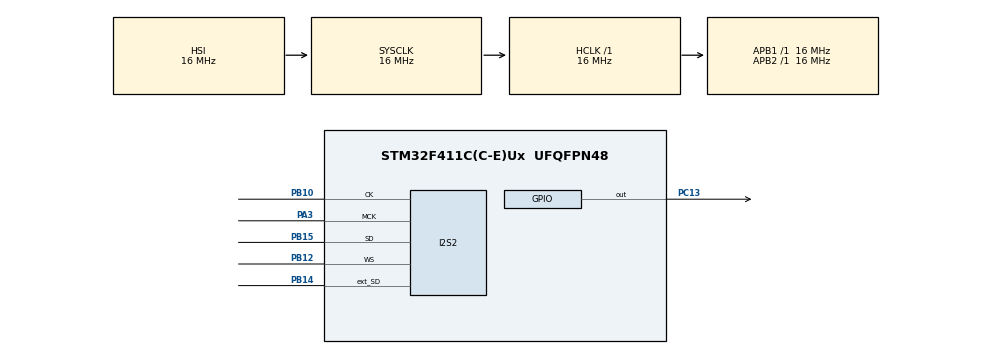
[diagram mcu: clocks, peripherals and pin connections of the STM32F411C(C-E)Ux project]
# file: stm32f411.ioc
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Dma.I2S2_EXT_RX.0.Direction=DMA_PERIPH_TO_MEMORY
Dma.I2S2_EXT_RX.0.FIFOMode=DMA_FIFOMODE_DISABLE
Dma.I2S2_EXT_RX.0.Instance=DMA1_Stream3
Dma.I2S2_EXT_RX.0.MemDataAlignment=DMA_MDATAALIGN_HALFWORD
Dma.I2S2_EXT_RX.0.MemInc=DMA_MINC_ENABLE
Dma.I2S2_EXT_RX.0.Mode=DMA_NORMAL
Dma.I2S2_EXT_RX.0.PeriphDataAlignment=DMA_PDATAALIGN_HALFWORD
Dma.I2S2_EXT_RX.0.PeriphInc=DMA_PINC_DISABLE
Dma.I2S2_EXT_RX.0.Priority=DMA_PRIORITY_LOW
Dma.Request0=I2S2_EXT_RX
Dma.Request1=SPI2_TX
Dma.SPI2_TX.1.Direction=DMA_MEMORY_TO_PERIPH
Dma.SPI2_TX.1.FIFOMode=DMA_FIFOMODE_DISABLE
Dma.SPI2_TX.1.Instance=DMA1_Stream4
Dma.SPI2_TX.1.MemDataAlignment=DMA_MDATAALIGN_HALFWORD
Dma.SPI2_TX.1.MemInc=DMA_MINC_ENABLE
Dma.SPI2_TX.1.Mode=DMA_CIRCULAR
Dma.SPI2_TX.1.PeriphDataAlignment=DMA_PDATAALIGN_HALFWORD
Dma.SPI2_TX.1.PeriphInc=DMA_PINC_DISABLE
Dma.SPI2_TX.1.Priority=DMA_PRIORITY_LOW
I2S2.AudioFreq=I2S_AUDIOFREQ_44K
I2S2.DataFormat=I2S_DATAFORMAT_24B
I2S2.ErrorAudioFreq=-5.3 %
I2S2.FullDuplexMode=I2S_FULLDUPLEXMODE_ENABLE
I2S2.Instance=SPI$Index
I2S2.RealAudioFreq=41.666 KHz
I2S2.VirtualMode=I2S_MODE_MASTER
Mcu.Family=STM32F4
Mcu.Name=STM32F411C(C-E)Ux
Mcu.Package=UFQFPN48
NVIC.DMA1_Stream3_IRQn=true\:0\:0\:false\:false\:true\:false\:true
NVIC.DMA1_Stream4_IRQn=true\:0\:0\:false\:false\:true\:false\:true
NVIC.PriorityGroup=NVIC_PRIORITYGROUP_4
PA3.Mode=Master_Clock_Activated
PA3.Signal=I2S2_MCK
PB10.Mode=Full_Duplex_Master
PB10.Signal=I2S2_CK
PB12.Mode=Full_Duplex_Master
PB12.Signal=I2S2_WS
PB14.Mode=Full_Duplex_Master
PB14.Signal=I2S2_ext_SD
PB15.Mode=Full_Duplex_Master
PB15.Signal=I2S2_SD
PC13-ANTI_TAMP.Signal=GPIO_Output
ProjectManager.HeapSize=0x200
ProjectManager.StackSize=0x400
ProjectManager.TargetToolchain=STM32CubeIDE
RCC.AHBFreq_Value=16000000
RCC.APB1Freq_Value=16000000
RCC.APB2Freq_Value=16000000
RCC.CortexFreq_Value=16000000
RCC.HSE_VALUE=25000000
RCC.HSI_VALUE=16000000
RCC.LSE_VALUE=32768
RCC.SYSCLKFreq_VALUE=16000000
RCC.VCOOutputFreq_Value=192000000
board=custom

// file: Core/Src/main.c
/* USER CODE BEGIN Header */
/**
  ******************************************************************************
  * @file           : main.c
  * @brief          : Main program body
  ******************************************************************************
  * @attention
  *
  * <h2><center>&copy; Copyright (c) 2020 STMicroelectronics.
  * All rights reserved.</center></h2>
  *
  * This software component is licensed by ST under BSD 3-Clause license,
  * the "License"; You may not use this file except in compliance with the
  * License. You may obtain a copy of the License at:
  *                        opensource.org/licenses/BSD-3-Clause
  *
  ******************************************************************************
  */
/* USER CODE END Header */
#include "main.h"

I2S_HandleTypeDef hi2s2;
DMA_HandleTypeDef hdma_i2s2_ext_rx;
DMA_HandleTypeDef hdma_spi2_tx;

/* USER CODE BEGIN PV */
#define SAMPLES			2048				// Total number of samples left and right
#define	BUF_SAMPLES		SAMPLES * 4		// Size of DMA tx/rx buffer samples * left/right * 2 for 32 bit samples

// DMA Buffers
uint16_t rxBuf[BUF_SAMPLES];
uint16_t txBuf[BUF_SAMPLES];

/* USER CODE END PV */

void SystemClock_Config(void);
static void MX_GPIO_Init(void);
static void MX_DMA_Init(void);
static void MX_I2S2_Init(void);

int main(void)
{

  /* MCU Configuration--------------------------------------------------------*/

  /* Reset of all peripherals, Initializes the Flash interface and the Systick. */
  HAL_Init();

  /* Configure the system clock */
  SystemClock_Config();

  /* Initialize all configured peripherals */
  MX_GPIO_Init();
  MX_DMA_Init();
  MX_I2S2_Init();
  /* USER CODE BEGIN 2 */

  HAL_I2SEx_TransmitReceive_DMA(&hi2s2, txBuf, rxBuf, SAMPLES*2 );

  /* USER CODE END 2 */

  /* Infinite loop */
  while (1)
  {

    /* USER CODE BEGIN 3 */
	  HAL_GPIO_TogglePin(GPIOC, GPIO_PIN_13 );
	  HAL_Delay(200);
  }
  /* USER CODE END 3 */
}

void SystemClock_Config(void)
{
  RCC_OscInitTypeDef RCC_OscInitStruct = {0};
  RCC_ClkInitTypeDef RCC_ClkInitStruct = {0};
  RCC_PeriphCLKInitTypeDef PeriphClkInitStruct = {0};

  /** Macro to configure the PLL multiplication factor
  */
  __HAL_RCC_PLL_PLLM_CONFIG(16);
  /** Macro to configure the PLL clock source
  */
  __HAL_RCC_PLL_PLLSOURCE_CONFIG(RCC_PLLSOURCE_HSI);
  /** Configure the main internal regulator output voltage
  */
  __HAL_RCC_PWR_CLK_ENABLE();
  __HAL_PWR_VOLTAGESCALING_CONFIG(PWR_REGULATOR_VOLTAGE_SCALE1);
  /** Initializes the RCC Oscillators according to the specified parameters
  * in the RCC_OscInitTypeDef structure.
  */
  RCC_OscInitStruct.OscillatorType = RCC_OSCILLATORTYPE_HSI;
  RCC_OscInitStruct.HSIState = RCC_HSI_ON;
  RCC_OscInitStruct.HSICalibrationValue = RCC_HSICALIBRATION_DEFAULT;
  RCC_OscInitStruct.PLL.PLLState = RCC_PLL_NONE;
  RCC_OscInitStruct.PLL.PLLSource = RCC_PLLSOURCE_HSI;
  if (HAL_RCC_OscConfig(&RCC_OscInitStruct) != HAL_OK)
  {
    Error_Handler();
  }
  /** Initializes the CPU, AHB and APB buses clocks
  */
  RCC_ClkInitStruct.ClockType = RCC_CLOCKTYPE_HCLK|RCC_CLOCKTYPE_SYSCLK
                              |RCC_CLOCKTYPE_PCLK1|RCC_CLOCKTYPE_PCLK2;
  RCC_ClkInitStruct.SYSCLKSource = RCC_SYSCLKSOURCE_HSI;
  RCC_ClkInitStruct.AHBCLKDivider = RCC_SYSCLK_DIV1;
  RCC_ClkInitStruct.APB1CLKDivider = RCC_HCLK_DIV1;
  RCC_ClkInitStruct.APB2CLKDivider = RCC_HCLK_DIV1;

  if (HAL_RCC_ClockConfig(&RCC_ClkInitStruct, FLASH_LATENCY_0) != HAL_OK)
  {
    Error_Handler();
  }
  PeriphClkInitStruct.PeriphClockSelection = RCC_PERIPHCLK_I2S;
  PeriphClkInitStruct.PLLI2S.PLLI2SN = 192;
  PeriphClkInitStruct.PLLI2S.PLLI2SM = 16;
  PeriphClkInitStruct.PLLI2S.PLLI2SR = 2;
  if (HAL_RCCEx_PeriphCLKConfig(&PeriphClkInitStruct) != HAL_OK)
  {
    Error_Handler();
  }
}

static void MX_I2S2_Init(void)
{

  hi2s2.Instance = SPI2;
  hi2s2.Init.Mode = I2S_MODE_MASTER_TX;
  hi2s2.Init.Standard = I2S_STANDARD_PHILIPS;
  hi2s2.Init.DataFormat = I2S_DATAFORMAT_24B;
  hi2s2.Init.MCLKOutput = I2S_MCLKOUTPUT_ENABLE;
  hi2s2.Init.AudioFreq = I2S_AUDIOFREQ_44K;
  hi2s2.Init.CPOL = I2S_CPOL_LOW;
  hi2s2.Init.ClockSource = I2S_CLOCK_PLL;
  hi2s2.Init.FullDuplexMode = I2S_FULLDUPLEXMODE_ENABLE;
  if (HAL_I2S_Init(&hi2s2) != HAL_OK)
  {
    Error_Handler();
  }

}

static void MX_DMA_Init(void)
{

  /* DMA controller clock enable */
  __HAL_RCC_DMA1_CLK_ENABLE();

  /* DMA interrupt init */
  /* DMA1_Stream3_IRQn interrupt configuration */
  HAL_NVIC_SetPriority(DMA1_Stream3_IRQn, 0, 0);
  HAL_NVIC_EnableIRQ(DMA1_Stream3_IRQn);
  /* DMA1_Stream4_IRQn interrupt configuration */
  HAL_NVIC_SetPriority(DMA1_Stream4_IRQn, 0, 0);
  HAL_NVIC_EnableIRQ(DMA1_Stream4_IRQn);

}

static void MX_GPIO_Init(void)
{
  GPIO_InitTypeDef GPIO_InitStruct = {0};

  /* GPIO Ports Clock Enable */
  __HAL_RCC_GPIOC_CLK_ENABLE();
  __HAL_RCC_GPIOA_CLK_ENABLE();
  __HAL_RCC_GPIOB_CLK_ENABLE();

  /*Configure GPIO pin Output Level */
  HAL_GPIO_WritePin(GPIOC, GPIO_PIN_13, GPIO_PIN_RESET);

  /*Configure GPIO pin : PC13 */
  GPIO_InitStruct.Pin = GPIO_PIN_13;
  GPIO_InitStruct.Mode = GPIO_MODE_OUTPUT_PP;
  GPIO_InitStruct.Pull = GPIO_NOPULL;
  GPIO_InitStruct.Speed = GPIO_SPEED_FREQ_LOW;
  HAL_GPIO_Init(GPIOC, &GPIO_InitStruct);

}

void Error_Handler(void)
{
}

/************************ (C) COPYRIGHT STMicroelectronics *****END OF FILE****/
